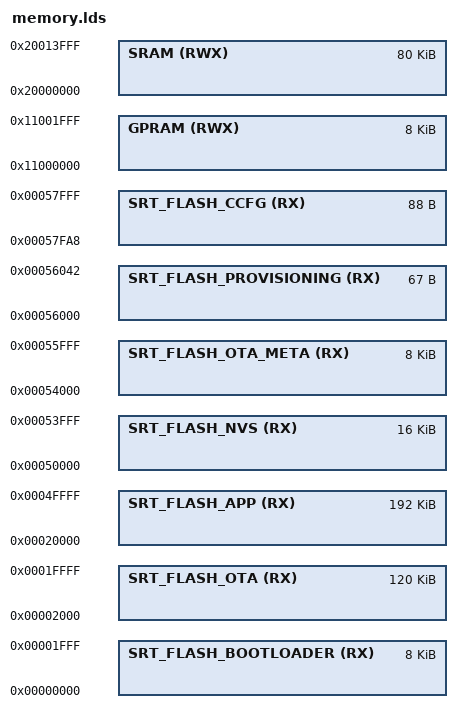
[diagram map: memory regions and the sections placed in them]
MEMORY
{
    SRT_FLASH_BOOTLOADER (RX)   : ORIGIN = 0x00000000, LENGTH = 0x00002000
    SRT_FLASH_OTA (RX)          : ORIGIN = 0x00002000, LENGTH = 0x0001e000
    SRT_FLASH_APP (RX)          : ORIGIN = 0x00020000, LENGTH = 0x00030000
    SRT_FLASH_NVS (RX)          : ORIGIN = 0x00050000, LENGTH = 0x00004000
    SRT_FLASH_OTA_META (RX)     : ORIGIN = 0x00054000, LENGTH = 0x00002000
    SRT_FLASH_PROVISIONING (RX) : ORIGIN = 0x00056000, LENGTH = 0x00000043
    SRT_FLASH_CCFG (RX)         : ORIGIN = 0x00057fa8, LENGTH = 0x00000058
    SRAM (RWX)                  : ORIGIN = 0x20000000, LENGTH = 0x00014000
    GPRAM (RWX)                 : ORIGIN = 0x11000000, LENGTH = 0x00002000
}
